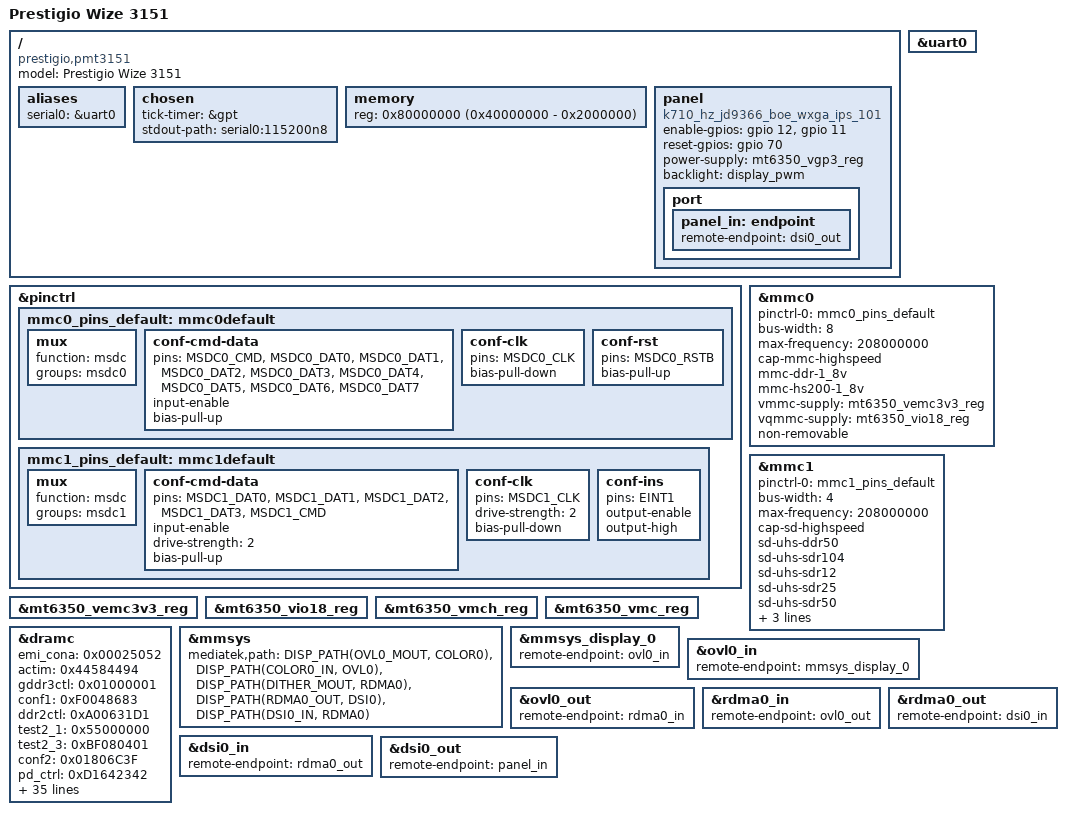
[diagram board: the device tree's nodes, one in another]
// SPDX-License-Identifier: GPL-2.0+

/dts-v1/;
#include "mt6580.dtsi"
#include "mt6350.dtsi"

/ {
  model = "Prestigio Wize 3151";
  compatible = "prestigio,pmt3151";

  aliases {
    serial0 = &uart0;
  };

  chosen {
    tick-timer = &gpt;
    stdout-path = "serial0:115200n8";
  };

  memory {
    #address-cells = <1>;
    #size-cells = <1>;
    device_type = "memory";

    // using last 32 MB leads to crash(is it used by something else like trustzone?)
    reg = <0x80000000 (0x40000000 - 0x2000000)>;
  };
};

&uart0 {
  status = "okay";
};

/*&uart1 {
  status = "okay";
};*/

&pinctrl {
  mmc0_pins_default: mmc0default {
    mux {
      function = "msdc";
      groups =  "msdc0";
    };

    conf-cmd-data {
      pins = "MSDC0_CMD", "MSDC0_DAT0", "MSDC0_DAT1",
             "MSDC0_DAT2", "MSDC0_DAT3", "MSDC0_DAT4",
             "MSDC0_DAT5", "MSDC0_DAT6", "MSDC0_DAT7";
      input-enable;
      bias-pull-up;
    };

    conf-clk {
      pins = "MSDC0_CLK";
      bias-pull-down;
    };

    conf-rst {
      pins = "MSDC0_RSTB";
      bias-pull-up;
    };
  };

  mmc1_pins_default: mmc1default {
    mux {
      function = "msdc";
      groups =  "msdc1";
    };

    conf-cmd-data {
      pins = "MSDC1_DAT0", "MSDC1_DAT1", "MSDC1_DAT2",
             "MSDC1_DAT3", "MSDC1_CMD";
      input-enable;
      drive-strength = <2>;
      bias-pull-up;
    };

    conf-clk {
      pins = "MSDC1_CLK";
      drive-strength = <2>;
      bias-pull-down;
    };

    conf-ins {
      pins = "EINT1";
      output-enable;
      output-high;
    };
  };
};

&mmc0 {
  pinctrl-names = "default";
  pinctrl-0 = <&mmc0_pins_default>;
  bus-width = <8>;
  max-frequency = <208000000>;
  cap-mmc-highspeed;
  mmc-ddr-1_8v;
  mmc-hs200-1_8v;
  vmmc-supply = <&mt6350_vemc3v3_reg>;
  vqmmc-supply = <&mt6350_vio18_reg>;
  non-removable;
  // status = "okay";
};

&mmc1 {
  pinctrl-names = "default";
  pinctrl-0 = <&mmc1_pins_default>;
  bus-width = <4>;
  max-frequency = <208000000>;
  cap-sd-highspeed;
  sd-uhs-ddr50;
  sd-uhs-sdr104;
  sd-uhs-sdr12;
  sd-uhs-sdr25;
  sd-uhs-sdr50;
  vmmc-supply = <&mt6350_vmch_reg>;
  vqmmc-supply = <&mt6350_vmc_reg>;
  cd-gpios = <&gpio 17 GPIO_ACTIVE_LOW>;
  status = "okay";
};

&mt6350_vemc3v3_reg {
  bootph-all;
};

&mt6350_vio18_reg {
  bootph-all;
};

&mt6350_vmch_reg {
  bootph-all;
};

&mt6350_vmc_reg {
  bootph-all;
};

&dramc {
  emi_cona = <0x00025052>;
  actim =    <0x44584494>;
  gddr3ctl = <0x01000001>;
  conf1 =    <0xF0048683>;
  ddr2ctl =  <0xA00631D1>;
  test2_1 =  <0x55000000>;
  test2_3 =  <0xBF080401>;
  conf2 =    <0x01806C3F>;
  pd_ctrl =  <0xD1642342>;
  actim1 =   <0x11000510>;
  misctl0 =  <0x07800000>;
  actim05t = <0x04002600>;
  modereg1 =  <0x00C30001>;
  modereg2 =  <0x00060002>;
  modereg10 = <0x00FF000A>;
  modereg63 = <0x0000003F>;

  rkXcoarse = <15>;
  rkXfine = <64>;

  ucsum = <2>;
  ucbest_step = <7>;

  rk0_dqidly1 = <0x7010501>;
  rk0_dqidly2 = <0x3040400>;
  rk0_dqidly3 = <0x4020300>;
  rk0_dqidly4 = <0x2010301>;
  rk0_dqidly5 = <0x2030400>;
  rk0_dqidly6 = <0x7040200>;
  rk0_dqidly7 = <0x3000603>;
  rk0_dqidly8 = <0x4030404>;
  rk0_r0deldly = <0x292C272E>;

  rk1_dqidly1 = <0x7020401>;
  rk1_dqidly2 = <0x3040300>;
  rk1_dqidly3 = <0x4030400>;
  rk1_dqidly4 = <0x2010401>;
  rk1_dqidly5 = <0x2020300>;
  rk1_dqidly6 = <0x7030100>;
  rk1_dqidly7 = <0x4000703>;
  rk1_dqidly8 = <0x6030505>;
  rk1_r0deldly = <0x2B2D282F>;

  dqodly1 = <0>;
  dqodly2 = <0>;
  dqodly3 = <0>;
  dqodly4 = <0>;
  padctl2 = <0>;
  padctl3 = <0>;
};

//DISPLAY
&mmsys {
  // ovl0 -> color0 -> internal
  // internal -> dither0 -> rdma0 -> dsi0
  // internal: color0 -> aal0 -> gamma0 -> dither0

  mediatek,path = <DISP_PATH(OVL0_MOUT,   COLOR0)>, // ovl -> color0
                  <DISP_PATH(COLOR0_IN,   OVL0)>,   //
                  <DISP_PATH(DITHER_MOUT, RDMA0)>,  // dither -> rdma
                  <DISP_PATH(RDMA0_OUT,   DSI0)>,   // rdma -> dsi0
                  <DISP_PATH(DSI0_IN,     RDMA0)>;  //
};

// mmsys_display_0 -> ovl0_in
&mmsys_display_0 {
  remote-endpoint = <&ovl0_in>;
};
&ovl0_in {
  remote-endpoint = <&mmsys_display_0>;
};

// ovl0_out -> rdma0_in
&ovl0_out {
  remote-endpoint = <&rdma0_in>;
};
&rdma0_in {
  remote-endpoint = <&ovl0_out>;
};

// rdma0_out -> dsi0_in
&rdma0_out {
  remote-endpoint = <&dsi0_in>;
};
&dsi0_in {
  remote-endpoint = <&rdma0_out>;
};

// dsi0_out -> panel_in
&dsi0_out {
  remote-endpoint = <&panel_in>;
};

/ {
  panel: panel {
    compatible = "k710_hz_jd9366_boe_wxga_ips_101";

    enable-gpios = <&gpio 12 GPIO_ACTIVE_HIGH>, // negative(ENN)
                   <&gpio 11 GPIO_ACTIVE_HIGH>; // positive(ENP)

    reset-gpios = <&gpio 70 GPIO_ACTIVE_HIGH>;

    power-supply = <&mt6350_vgp3_reg>;

    backlight = <&display_pwm>;

    port {
      panel_in: endpoint {
        remote-endpoint = <&dsi0_out>;
      };
    };
  };
};
